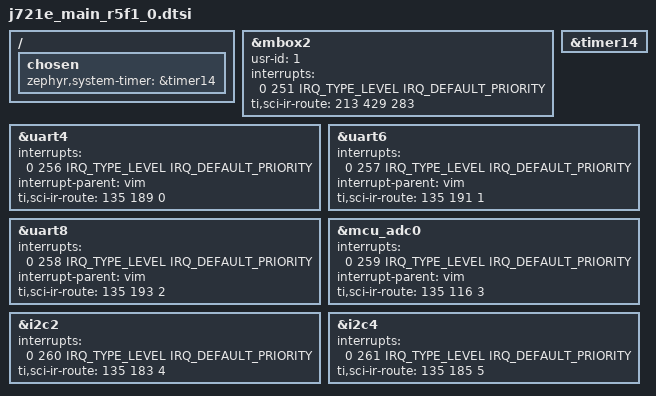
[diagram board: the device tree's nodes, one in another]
/*
 * Copyright (c) 2026 Dhruv Menon <dhruvmenon1104@gmail.com>
 *
 * SPDX-License-Identifier: Apache-2.0
 */

#include <ti/j721e_main_r5.dtsi>

/ {
	chosen {
		zephyr,system-timer = &timer14;
	};
};

&mbox2 {
	usr-id = <1>;
	/*
	 * Mailbox cluster 2 user 1 enters NAVSS0_INTR_ROUTER_0 (TI-SCI device 213)
	 * at input 429; output 283 of host MAIN_1_R5_0's range is wired to this
	 * core's VIM line 251 (outputs 256..287 = VIM 224..255).
	 */
	interrupts = <0 251 IRQ_TYPE_LEVEL IRQ_DEFAULT_PRIORITY>;
	ti,sci-ir-route = <213 429 283>;
	status = "okay";
};

&timer14 {
	status = "okay";
};

/*
 * MAIN UART3..9 reach R5FSS1 only through R5FSS1_INTROUTER0 (TI-SCI device
 * 135; its outputs 0..31 are this core's VIM lines 256..287, host MAIN_1_R5_0
 * owns outputs 0..127). Routed here: UART4 in 189 -> out 0 (VIM 256), UART6
 * in 191 -> out 1 (VIM 257), UART8 in 193 -> out 2 (VIM 258), MCU_ADC0 in
 * 116 -> out 3 (VIM 259), I2C2 in 183 -> out 4 (VIM 260), I2C4 in 185 -> out 5
 * (VIM 261).
 */
&uart4 {
	interrupts = <0 256 IRQ_TYPE_LEVEL IRQ_DEFAULT_PRIORITY>;
	interrupt-parent = <&vim>;
	ti,sci-ir-route = <135 189 0>;
};

&uart6 {
	interrupts = <0 257 IRQ_TYPE_LEVEL IRQ_DEFAULT_PRIORITY>;
	interrupt-parent = <&vim>;
	ti,sci-ir-route = <135 191 1>;
};

&uart8 {
	interrupts = <0 258 IRQ_TYPE_LEVEL IRQ_DEFAULT_PRIORITY>;
	interrupt-parent = <&vim>;
	ti,sci-ir-route = <135 193 2>;
};

&mcu_adc0 {
	interrupts = <0 259 IRQ_TYPE_LEVEL IRQ_DEFAULT_PRIORITY>;
	interrupt-parent = <&vim>;
	ti,sci-ir-route = <135 116 3>;
};

&i2c2 {
	interrupts = <0 260 IRQ_TYPE_LEVEL IRQ_DEFAULT_PRIORITY>;
	ti,sci-ir-route = <135 183 4>;
};

&i2c4 {
	interrupts = <0 261 IRQ_TYPE_LEVEL IRQ_DEFAULT_PRIORITY>;
	ti,sci-ir-route = <135 185 5>;
};
